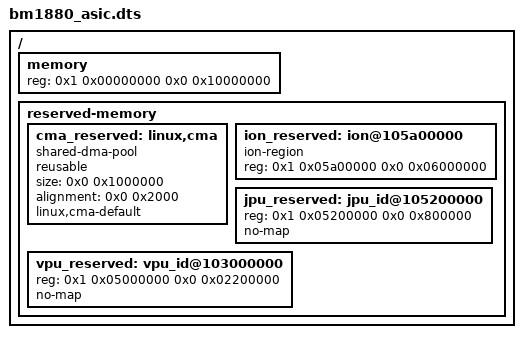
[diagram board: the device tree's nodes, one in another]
/dts-v1/;

#include "bm1880_asic.dtsi"

/ {
	memory {
		reg = <0x1 0x00000000 0x0 0x10000000>; // 256MB
		device_type = "memory";
	};

	reserved-memory {
		#address-cells = <0x2>;
		#size-cells = <0x2>;
		ranges;

		cma_reserved: linux,cma {
			compatible = "shared-dma-pool";
			reusable;
			size = <0x0 0x1000000>; // 16MB
			alignment = <0x0 0x2000>; // 8KB
			linux,cma-default;
		};

		ion_reserved: ion@105a00000 {
			compatible = "ion-region";
			reg = <0x1 0x05a00000 0x0 0x06000000>; // 96MB
		};

		jpu_reserved: jpu_id@105200000 {
			reg = <0x1 0x05200000 0x0 0x800000>; // 8M
			no-map;
		};

		vpu_reserved: vpu_id@103000000 {
			reg = <0x1 0x05000000 0x0 0x02200000>; // 34M
			no-map;
		};
	};
};
